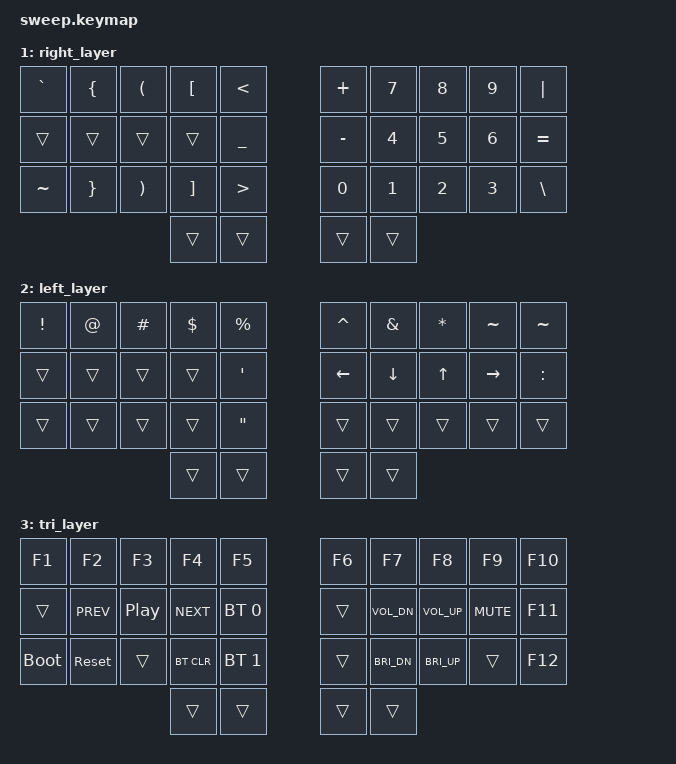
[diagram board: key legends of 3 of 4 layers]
// Copyright (c) 2022 The ZMK Contributors
// SPDX-License-Identifier: MIT

#include <behaviors.dtsi>
#include <dt-bindings/zmk/keys.h>
#include <dt-bindings/zmk/bt.h>

// Home row mods macro
#define HRML(k1,k2,k3,k4) &ht LCTRL k1  &ht LALT k2  &ht LGUI k3  &ht LSHFT k4
#define HRMR(k1,k2,k3,k4) &ht RSHFT k1  &ht RGUI k2  &ht RALT k3  &ht RCTRL k4

// Cut Copy Paste macros
#define HTL(key) &htl LG(key) key

/ {
    behaviors {
        ht: hold_tap {
            compatible = "zmk,behavior-hold-tap";
            #binding-cells = <2>;
            flavor = "balanced";
            tapping-term-ms = <200>;
            quick-tap-ms = <150>;
            require-prior-idle-ms = <150>;
            bindings = <&kp>, <&kp>;
        };
        htl: hold_tap_long {
            compatible = "zmk,behavior-hold-tap";
            #binding-cells = <2>;
            flavor = "tap-preferred";
            tapping-term-ms = <400>;
            bindings = <&kp>, <&kp>;
        };
        td_mt1: tap_dance_l1 {
            compatible = "zmk,behavior-tap-dance";
            #binding-cells = <0>;
            tapping-term-ms = <200>;
            bindings = <&mo 1>, <&tog 1>;
        };
        td_mt2: tap_dance_l2 {
            compatible = "zmk,behavior-tap-dance";
            #binding-cells = <0>;
            tapping-term-ms = <200>;
            bindings = <&mo 2>, <&tog 2>;
        };
        // Tap dance too slow with hold behavior
        // Workaround below (see https://github.com/zmkfirmware/zmk/issues/1691#issuecomment-1455196468)
        td_l1: tap_dance_layer_1 {
            compatible = "zmk,behavior-tap-dance";
            #binding-cells = <0>;
            tapping-term-ms = <200>;
            bindings = <&lt 1 SQT>, <&tog 1>;
        };
        td_l2: tap_dance_layer_2 {
            compatible = "zmk,behavior-tap-dance";
            #binding-cells = <0>;
            tapping-term-ms = <200>;
            bindings = <&lt 2 TAB>, <&tog 2>;
        };
        td_l1_inner: td_l1_inner {
            compatible = "zmk,behavior-tap-dance";
            label = "td_l1_inner";
            #binding-cells = <0>;
            tapping-term-ms = <200>;
            bindings = <&kp SQT>, <&tog 1>;
        };
        td_l1_fast: td_l1_fast {
            compatible = "zmk,behavior-hold-tap";
            label = "td_l1_fast";
            #binding-cells = <2>;
            flavor = "tap-preferred";
            tapping-term-ms = <200>;
            bindings = <&mo>, <&td_l1_inner>;
        };
        td_l2_inner: td_l2_inner {
            compatible = "zmk,behavior-tap-dance";
            label = "td_l2_inner";
            #binding-cells = <0>;
            tapping-term-ms = <200>;
            bindings = <&kp TAB>, <&tog 2>;
        };
        td_l2_fast: td_l2_fast {
            compatible = "zmk,behavior-hold-tap";
            label = "td_l2_fast";
            #binding-cells = <2>;
            flavor = "tap-preferred";
            tapping-term-ms = <200>;
            bindings = <&mo>, <&td_l2_inner>;
        };
    };

    combos {
        compatible = "zmk,combos";
        combo_enter {
            timeout-ms = <50>;
            key-positions = <31 32>;
            bindings = <&kp RET>;
        };
        combo_escl {
            timeout-ms = <50>;
            key-positions = <12 13>;
            bindings = <&kp ESC>;
        };
        combo_escr {
            timeout-ms = <50>;
            key-positions = <16 17>;
            bindings = <&kp ESC>;
        };
        combo_caps {
            timeout-ms = <50>;
            key-positions = <6 7>;
            bindings = <&kp CAPS>;
        };
        combo_tab {
            timeout-ms = <50>;
            key-positions = <2 3>;
            bindings = <&kp TAB>;
        };
    };

    conditional_layers {
        compatible = "zmk,conditional-layers";
        tri_layer {
            if-layers = <1 2>;
            then-layer = <3>;
        };
    };

    keymap {
        compatible = "zmk,keymap";
        default_layer {
            bindings = <
        //╭──────────┬──────────┬──────────┬──────────┬──────────╮   ╭──────────┬──────────┬──────────┬──────────┬──────────╮
        //│  Q       │  W       │  E       │  R       │  T       │   │  Y       │  U       │  I       │  O       │  P       │
            &kp Q      &kp W      &kp E      &kp R      &kp T          &kp Y      &kp U      &kp I      &kp O      &kp P
        //├──────────┼──────────┼──────────┼──────────┼──────────┤   ├──────────┼──────────┼──────────┼──────────┼──────────┤
        //│  A       │  S       │  D       │  F       │  G       │   │  H       │  J       │  K       │  L       │ ; :      │
            HRML(A,        S,         D,         F)     &kp G          &kp H      HRMR(J,        K,         L,       SEMI)
        //├──────────┼──────────┼──────────┼──────────┼──────────┤   ├──────────┼──────────┼──────────┼──────────┼──────────┤
        //│  Z       │  X       │  C       │  V       │  B       │   │  N       │  M       │ , <      │ . >      │ / ?      │
            &kp Z      HTL(X)     HTL(C)     HTL(V)     &kp B          &kp N      &kp M      &kp COMMA  &kp DOT    &kp FSLH
        //╰──────────┴──────────┴──────────┼──────────┼──────────┤   ├──────────┼──────────┼──────────┴──────────┴──────────╯
                                             &td_mt2    &kp BSPC       &kp SPACE  &td_mt1
        //                                 ╰──────────┴──────────╯   ╰──────────┴──────────╯
            >;
        };

        right_layer {
            bindings = <
        //╭──────────┬──────────┬──────────┬──────────┬──────────╮   ╭──────────┬──────────┬──────────┬──────────┬──────────╮
        //│  ` ~     │  {       │  (       │  [       │  <       │   │  +       │  7 &     │  8 *     │  9 (     │  |       │
            &kp GRAVE  &kp LBRC   &kp LPAR   &kp LBKT   &kp LT         &kp PLUS   &kp N7     &kp N8     &kp N9     &kp PIPE
        //├──────────┼──────────┼──────────┼──────────┼──────────┤   ├──────────┼──────────┼──────────┼──────────┼──────────┤
        //│          │          │          │          │  _       │   │  - _     │  4 $     │  5 %     │  6 ^     │  = +     │
            &trans     &trans     &trans     &trans     &kp UNDER      &kp MINUS  &kp N4     &kp N5     &kp N6     &kp EQUAL
        //├──────────┼──────────┼──────────┼──────────┼──────────┤   ├──────────┼──────────┼──────────┼──────────┼──────────┤
        //│  ~       │  }       │  )       │  ]       │  >       │   │  0 )     │  1 !     │  2 @     │  3 #     │  \ |     │
            &kp TILDE  &kp RBRC   &kp RPAR   &kp RBKT   &kp GT         &kp N0     &kp N1     &kp N2     &kp N3     &kp BSLH
        //╰──────────┴──────────┴──────────┼──────────┼──────────┤   ├──────────┼──────────┼──────────┴──────────┴──────────╯
                                             &trans     &trans         &trans     &trans
        //                                 ╰──────────┴──────────╯   ╰──────────┴──────────╯
            >;
        };

        left_layer {
            bindings = <
        //╭──────────┬──────────┬──────────┬──────────┬──────────╮   ╭──────────┬──────────┬──────────┬──────────┬──────────╮
        //│  !       │  @       │  #       │  $       │  %       │   │  ^       │  &       │  *       │  ~       │  ~       │
            &kp EXCL   &kp AT     &kp HASH   &kp DLLR   &kp PRCNT      &kp CARET  &kp AMPS   &kp ASTRK  &kp TILDE  &kp TILDE
        //├──────────┼──────────┼──────────┼──────────┼──────────┤   ├──────────┼──────────┼──────────┼──────────┼──────────┤
        //│          │          │          │          │  ' "     │   │          │          │          │          │  :       │
            &trans     &trans     &trans     &trans     &kp SQT        &kp LEFT   &kp DOWN   &kp UP     &kp RIGHT  &kp COLON
        //├──────────┼──────────┼──────────┼──────────┼──────────┤   ├──────────┼──────────┼──────────┼──────────┼──────────┤
        //│          │          │          │          │  "       │   │          │          │          │          │          │
            &trans     &trans     &trans     &trans     &kp DQT        &trans     &trans     &trans     &trans     &trans
        //╰──────────┴──────────┴──────────┼──────────┼──────────┤   ├──────────┼──────────┼──────────┴──────────┴──────────╯
                                             &trans     &trans         &trans     &trans
        //                                 ╰──────────┴──────────╯   ╰──────────┴──────────╯
            >;
        };

        tri_layer {
            bindings = <
        //╭──────────┬──────────┬──────────┬──────────┬──────────╮   ╭──────────┬──────────┬──────────┬──────────┬──────────╮
        //│          │          │          │          │          │   │          │          │          │          │          │
            &kp F1     &kp F2     &kp F3     &kp F4     &kp F5         &kp F6     &kp F7     &kp F8     &kp F9     &kp F10
        //├──────────┼──────────┼──────────┼──────────┼──────────┤   ├──────────┼──────────┼──────────┼──────────┼──────────┤
        //│          │          │          │          │PROFILE 0 │   │          │          │          │          │          │
           &trans      &kp C_PREV &kp C_PP   &kp C_NEXT &bt BT_SEL 0    &trans   &kp C_VOL_DN &kp C_VOL_UP &kp K_MUTE &kp F11
        //├──────────┼──────────┼──────────┼──────────┼──────────┤   ├──────────┼──────────┼──────────┼──────────┼──────────┤
        //│BOOTLOADER│ RESET    │          │ CLEAR BT │PROFILE 1 │   │          │          │          │          │          │
          &bootloader &sys_reset  &trans    &bt BT_CLR &bt BT_SEL 1    &trans   &kp C_BRI_DN &kp C_BRI_UP &trans   &kp F12
        //╰──────────┴──────────┴──────────┼──────────┼──────────┤   ├──────────┼──────────┼──────────┴──────────┴──────────╯
                                             &trans     &trans         &trans     &trans
        //                                 ╰──────────┴──────────╯   ╰──────────┴──────────╯
            >;
        };
    };
};
